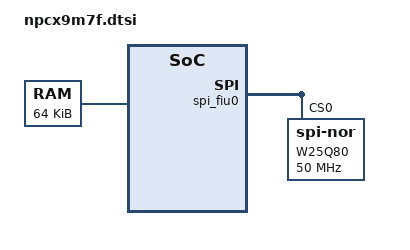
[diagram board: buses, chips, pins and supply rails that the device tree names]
/*
 * Copyright (c) 2022 Nuvoton Technology Corporation.
 *
 * SPDX-License-Identifier: Apache-2.0
 */

#include <mem.h>
#include "npcx9.dtsi"

/ {
	flash0: flash@10070000 {
		reg = <0x10070000 DT_SIZE_K(320)>;
	};

	flash1: flash@64000000 {
		reg = <0x64000000 DT_SIZE_K(1024)>;
	};

	sram0: memory@200c0000 {
		compatible = "mmio-sram";
		reg = <0x200C0000 DT_SIZE_K(64)>;
	};

	soc-id {
		device-id = <0x22>;
	};
};

&spi_fiu0 {
	int_flash: w25q80@0 {
		compatible ="jedec,spi-nor";
		/* 8388608 bits = 1 Mbytes */
		size = <0x800000>;
		label = "W25Q80";
		reg = <0>;
		spi-max-frequency = <50000000>;
		status = "okay";
		jedec-id = [ef 40 14];
	};
};
